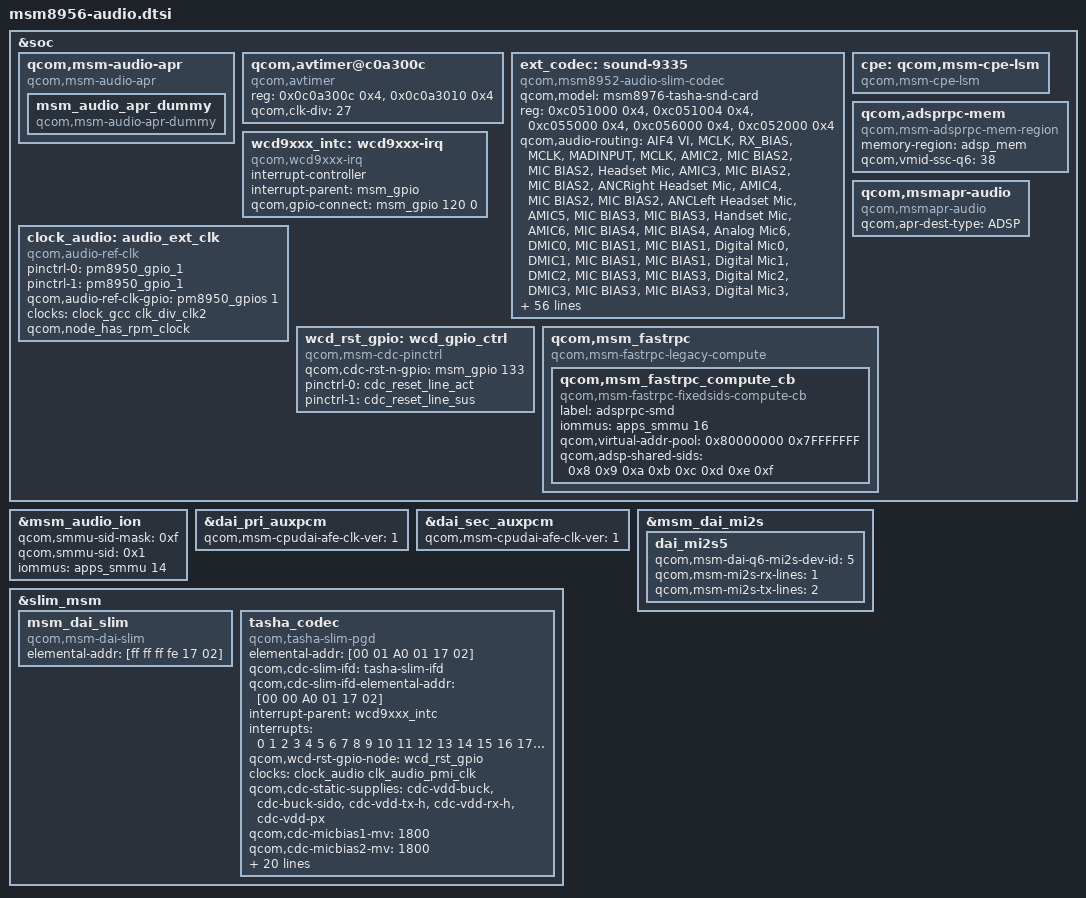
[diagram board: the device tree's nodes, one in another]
/*
 * Copyright (c) 2014-2015, The Linux Foundation. All rights reserved.
 * Copyright (c) 2019, Pavel Dubrova <pashadubrova@gmail.com>
 *
 * This program is free software; you can redistribute it and/or modify
 * it under the terms of the GNU General Public License version 2 and
 * only version 2 as published by the Free Software Foundation.
 *
 * This program is distributed in the hope that it will be useful,
 * but WITHOUT ANY WARRANTY; without even the implied warranty of
 * MERCHANTABILITY or FITNESS FOR A PARTICULAR PURPOSE.  See the
 * GNU General Public License for more details.
 */ 

#include "msm-audio-lpass.dtsi"
#include "msm8956-wsa881x.dtsi"

&soc {
	qcom,msm-audio-apr {
		compatible = "qcom,msm-audio-apr";
		msm_audio_apr_dummy {
			compatible = "qcom,msm-audio-apr-dummy";
		};
	};

	qcom,avtimer@c0a300c {
		compatible = "qcom,avtimer";
		reg = <0x0c0a300c 0x4>,
			<0x0c0a3010 0x4>;
		reg-names = "avtimer_lsb_addr", "avtimer_msb_addr";
		qcom,clk-div = <27>;
	};

	ext_codec: sound-9335 {
		compatible = "qcom,msm8952-audio-slim-codec";
		qcom,model = "msm8976-tasha-snd-card";

		reg = <0xc051000 0x4>,
			<0xc051004 0x4>,
			<0xc055000 0x4>,
			<0xc056000 0x4>,
			<0xc052000 0x4>;
		reg-names = "csr_gp_io_mux_mic_ctl",
			"csr_gp_io_mux_spkr_ctl",
			"csr_gp_io_lpaif_pri_pcm_pri_mode_muxsel",
			"csr_gp_io_lpaif_sec_pcm_sec_mode_muxsel",
			"csr_gp_io_mux_quin_ctl";

		qcom,audio-routing =
			"AIF4 VI", "MCLK",
			"RX_BIAS", "MCLK",
			"MADINPUT", "MCLK",
			"AMIC2", "MIC BIAS2",
			"MIC BIAS2", "Headset Mic",
			"AMIC3", "MIC BIAS2",
			"MIC BIAS2", "ANCRight Headset Mic",
			"AMIC4", "MIC BIAS2",
			"MIC BIAS2", "ANCLeft Headset Mic",
			"AMIC5", "MIC BIAS3",
			"MIC BIAS3", "Handset Mic",
			"AMIC6", "MIC BIAS4",
			"MIC BIAS4", "Analog Mic6",
			"DMIC0", "MIC BIAS1",
			"MIC BIAS1", "Digital Mic0",
			"DMIC1", "MIC BIAS1",
			"MIC BIAS1", "Digital Mic1",
			"DMIC2", "MIC BIAS3",
			"MIC BIAS3", "Digital Mic2",
			"DMIC3", "MIC BIAS3",
			"MIC BIAS3", "Digital Mic3",
			"DMIC4", "MIC BIAS4",
			"MIC BIAS4", "Digital Mic4",
			"DMIC5", "MIC BIAS4",
			"MIC BIAS4", "Digital Mic5",
			"SpkrLeft IN", "SPK1 OUT",
			"SpkrRight IN", "SPK2 OUT";

		qcom,msm-gpios =
			"us_eu_gpio";
		qcom,pinctrl-names =
			"all_off",
			"us_eu_gpio_act";
		pinctrl-names =
			"all_off",
			"us_eu_gpio_act";

		pinctrl-0 = <&cross_conn_det_sus>;// &pm8950_gpio_7>;
		pinctrl-1 = <&cross_conn_det_act>;// &pm8950_gpio_7>;
		qcom,cdc-us-euro-gpios = <&msm_gpio 144 0>;

		qcom,msm-mbhc-hphl-swh = <0>;
		qcom,msm-mbhc-gnd-swh = <0>;
		qcom,tasha-mclk-clk-freq = <9600000>;

		asoc-platform = <&pcm0>, <&pcm1>, <&pcm2>, <&voip>, <&voice>,
				<&loopback>, <&compress>, <&hostless>,
				<&afe>, <&lsm>, <&routing>, <&cpe>,
				<&pcm_noirq>;
		asoc-platform-names = "msm-pcm-dsp.0", "msm-pcm-dsp.1", "msm-pcm-dsp.2",
				"msm-voip-dsp", "msm-pcm-voice", "msm-pcm-loopback",
				"msm-compress-dsp", "msm-pcm-hostless", "msm-pcm-afe",
				"msm-lsm-client", "msm-pcm-routing", "msm-cpe-lsm",
				"msm-pcm-dsp-noirq";

		asoc-cpu = <&dai_pri_auxpcm>, <&dai_sec_auxpcm>, <&dai_hdmi>,
				<&dai_mi2s2>, <&dai_mi2s3>, <&dai_mi2s5>,
				<&sb_0_rx>, <&sb_0_tx>, <&sb_1_rx>, <&sb_1_tx>,
				<&sb_2_rx>, <&sb_2_tx>, <&sb_3_rx>, <&sb_3_tx>,
				<&sb_4_rx>, <&sb_4_tx>, <&sb_5_tx>, <&afe_pcm_rx>,
				<&afe_pcm_tx>, <&afe_proxy_rx>, <&afe_proxy_tx>,
				<&incall_record_rx>, <&incall_record_tx>,
				<&incall_music_rx>, <&incall_music_2_rx>,
				<&sb_5_rx>,  <&bt_sco_rx>,
				<&bt_sco_tx>, <&int_fm_rx>, <&int_fm_tx>,
				<&sb_6_rx>;
		asoc-cpu-names = "msm-dai-q6-auxpcm.1",	"msm-dai-q6-auxpcm.2",
				"msm-dai-q6-mi2s-hdmi.4118",
				"msm-dai-q6-mi2s.2",
				"msm-dai-q6-mi2s.3", "msm-dai-q6-mi2s.5",
				"msm-dai-q6-dev.16384", "msm-dai-q6-dev.16385",
				"msm-dai-q6-dev.16386", "msm-dai-q6-dev.16387",
				"msm-dai-q6-dev.16388", "msm-dai-q6-dev.16389",
				"msm-dai-q6-dev.16390", "msm-dai-q6-dev.16391",
				"msm-dai-q6-dev.16392", "msm-dai-q6-dev.16393",
				"msm-dai-q6-dev.16395", "msm-dai-q6-dev.224",
				"msm-dai-q6-dev.225", "msm-dai-q6-dev.241",
				"msm-dai-q6-dev.240", "msm-dai-q6-dev.32771",
				"msm-dai-q6-dev.32772", "msm-dai-q6-dev.32773",
				"msm-dai-q6-dev.32770", "msm-dai-q6-dev.16394",
				"msm-dai-q6-dev.12288", "msm-dai-q6-dev.12289",
				"msm-dai-q6-dev.12292", "msm-dai-q6-dev.12293",
				"msm-dai-q6-dev.16396";

		asoc-codec = <&stub_codec>;
		asoc-codec-names = "msm-stub-codec.1";

		qcom,wsa-max-devs = <2>;
		qcom,wsa-devs = <&wsa881x_211>, <&wsa881x_212>,
						<&wsa881x_213>, <&wsa881x_214>;
		qcom,wsa-aux-dev-prefix = "SpkrLeft", "SpkrRight",
				"SpkrLeft", "SpkrRight";
	};

	cpe: qcom,msm-cpe-lsm {
		compatible = "qcom,msm-cpe-lsm";
	};

	wcd9xxx_intc: wcd9xxx-irq {
		compatible = "qcom,wcd9xxx-irq";
		interrupt-controller;
		#interrupt-cells = <1>;
		interrupt-parent = <&msm_gpio>;
		qcom,gpio-connect = <&msm_gpio 120 0>;
	};

	clock_audio: audio_ext_clk {
		compatible = "qcom,audio-ref-clk";
		pinctrl-names = "active", "sleep";
		pinctrl-0 = <&pm8950_gpio_1>;
		pinctrl-1 = <&pm8950_gpio_1>;
		qcom,audio-ref-clk-gpio = <&pm8950_gpios 1 0>;
		clock-names = "osr_clk";
		clocks = <&clock_gcc clk_div_clk2>;
		qcom,node_has_rpm_clock;
		#clock-cells = <1>;
	};

	wcd_rst_gpio: wcd_gpio_ctrl {
		compatible = "qcom,msm-cdc-pinctrl";
		qcom,cdc-rst-n-gpio = <&msm_gpio 133 0>;
		pinctrl-names = "aud_active", "aud_sleep";
		pinctrl-0 = <&cdc_reset_line_act>;
		pinctrl-1 = <&cdc_reset_line_sus>;
	};

	qcom,adsprpc-mem {
		compatible = "qcom,msm-adsprpc-mem-region";
		memory-region = <&adsp_mem>;
		qcom,vmid-ssc-q6 = <38>;
	};

	qcom,msmapr-audio {
		compatible = "qcom,msmapr-audio";
		qcom,apr-dest-type = "ADSP";
	};

	qcom,msm_fastrpc {
		compatible = "qcom,msm-fastrpc-legacy-compute";
		qcom,msm_fastrpc_compute_cb {
			compatible = "qcom,msm-fastrpc-fixedsids-compute-cb";
			label = "adsprpc-smd";
			iommus = <&apps_smmu 16>;

			qcom,virtual-addr-pool = <0x80000000 0x7FFFFFFF>;
			qcom,adsp-shared-sids =
					<0x8 0x9 0xa 0xb 0xc 0xd 0xe 0xf>;
		};
	};
};

&msm_audio_ion {
	qcom,smmu-sid-mask = /bits/ 64 <0xf>;
	qcom,smmu-sid = <0x1>;
	iommus = <&apps_smmu 14>;
};

&dai_pri_auxpcm {
	qcom,msm-cpudai-afe-clk-ver = <1>;
};

&dai_sec_auxpcm {
	qcom,msm-cpudai-afe-clk-ver = <1>;
};

&msm_dai_mi2s {
	dai_mi2s5 {
		qcom,msm-dai-q6-mi2s-dev-id = <5>;
		qcom,msm-mi2s-rx-lines = <1>;
		qcom,msm-mi2s-tx-lines = <2>;
	};
};

&slim_msm {
	msm_dai_slim {
		compatible = "qcom,msm-dai-slim";
		elemental-addr = [ff ff ff fe 17 02];
	};

	tasha_codec {
		compatible = "qcom,tasha-slim-pgd";
		elemental-addr = [00 01 A0 01 17 02];

		qcom,cdc-slim-ifd = "tasha-slim-ifd";
		qcom,cdc-slim-ifd-elemental-addr = [00 00 A0 01 17 02];

		interrupt-parent = <&wcd9xxx_intc>;
		interrupts = <0 1 2 3 4 5 6 7 8 9 10 11 12 13 14 15 16
				17 18 19 20 21 22 23 24 25 26 27 28 29 30>;

		qcom,wcd-rst-gpio-node = <&wcd_rst_gpio>;

		clock-names = "wcd_clk";
		clocks = <&clock_audio clk_audio_pmi_clk>;

		qcom,cdc-static-supplies = "cdc-vdd-buck",
				"cdc-buck-sido",
				"cdc-vdd-tx-h",
				"cdc-vdd-rx-h",
				"cdc-vdd-px";

		qcom,cdc-micbias1-mv = <1800>;
		qcom,cdc-micbias2-mv = <1800>;
		qcom,cdc-micbias3-mv = <1800>;
		qcom,cdc-micbias4-mv = <1800>;

		qcom,cdc-dmic-sample-rate = <4800000>;
		qcom,cdc-mclk-clk-rate = <9600000>;
		qcom,cdc-mad-dmic-rate = <600000>;

		cdc-vdd-buck-supply = <&eldo2_8976>;
		qcom,cdc-vdd-buck-voltage = <1800000 1800000>;
		qcom,cdc-vdd-buck-current = <650000>;

		cdc-buck-sido-supply = <&eldo2_8976>;
		qcom,cdc-buck-sido-voltage = <1800000 1800000>;
		qcom,cdc-buck-sido-current = <250000>;

		cdc-vdd-tx-h-supply = <&pm8950_l5>;
		qcom,cdc-vdd-tx-h-voltage = <1800000 1800000>;
		qcom,cdc-vdd-tx-h-current = <25000>;

		cdc-vdd-rx-h-supply = <&pm8950_l5>;
		qcom,cdc-vdd-rx-h-voltage = <1800000 1800000>;
		qcom,cdc-vdd-rx-h-current = <25000>;

		cdc-vdd-px-supply = <&pm8950_l5>;
		qcom,cdc-vdd-px-voltage = <1800000 1800000>;
		qcom,cdc-vdd-px-current = <10000>;
	};
};
